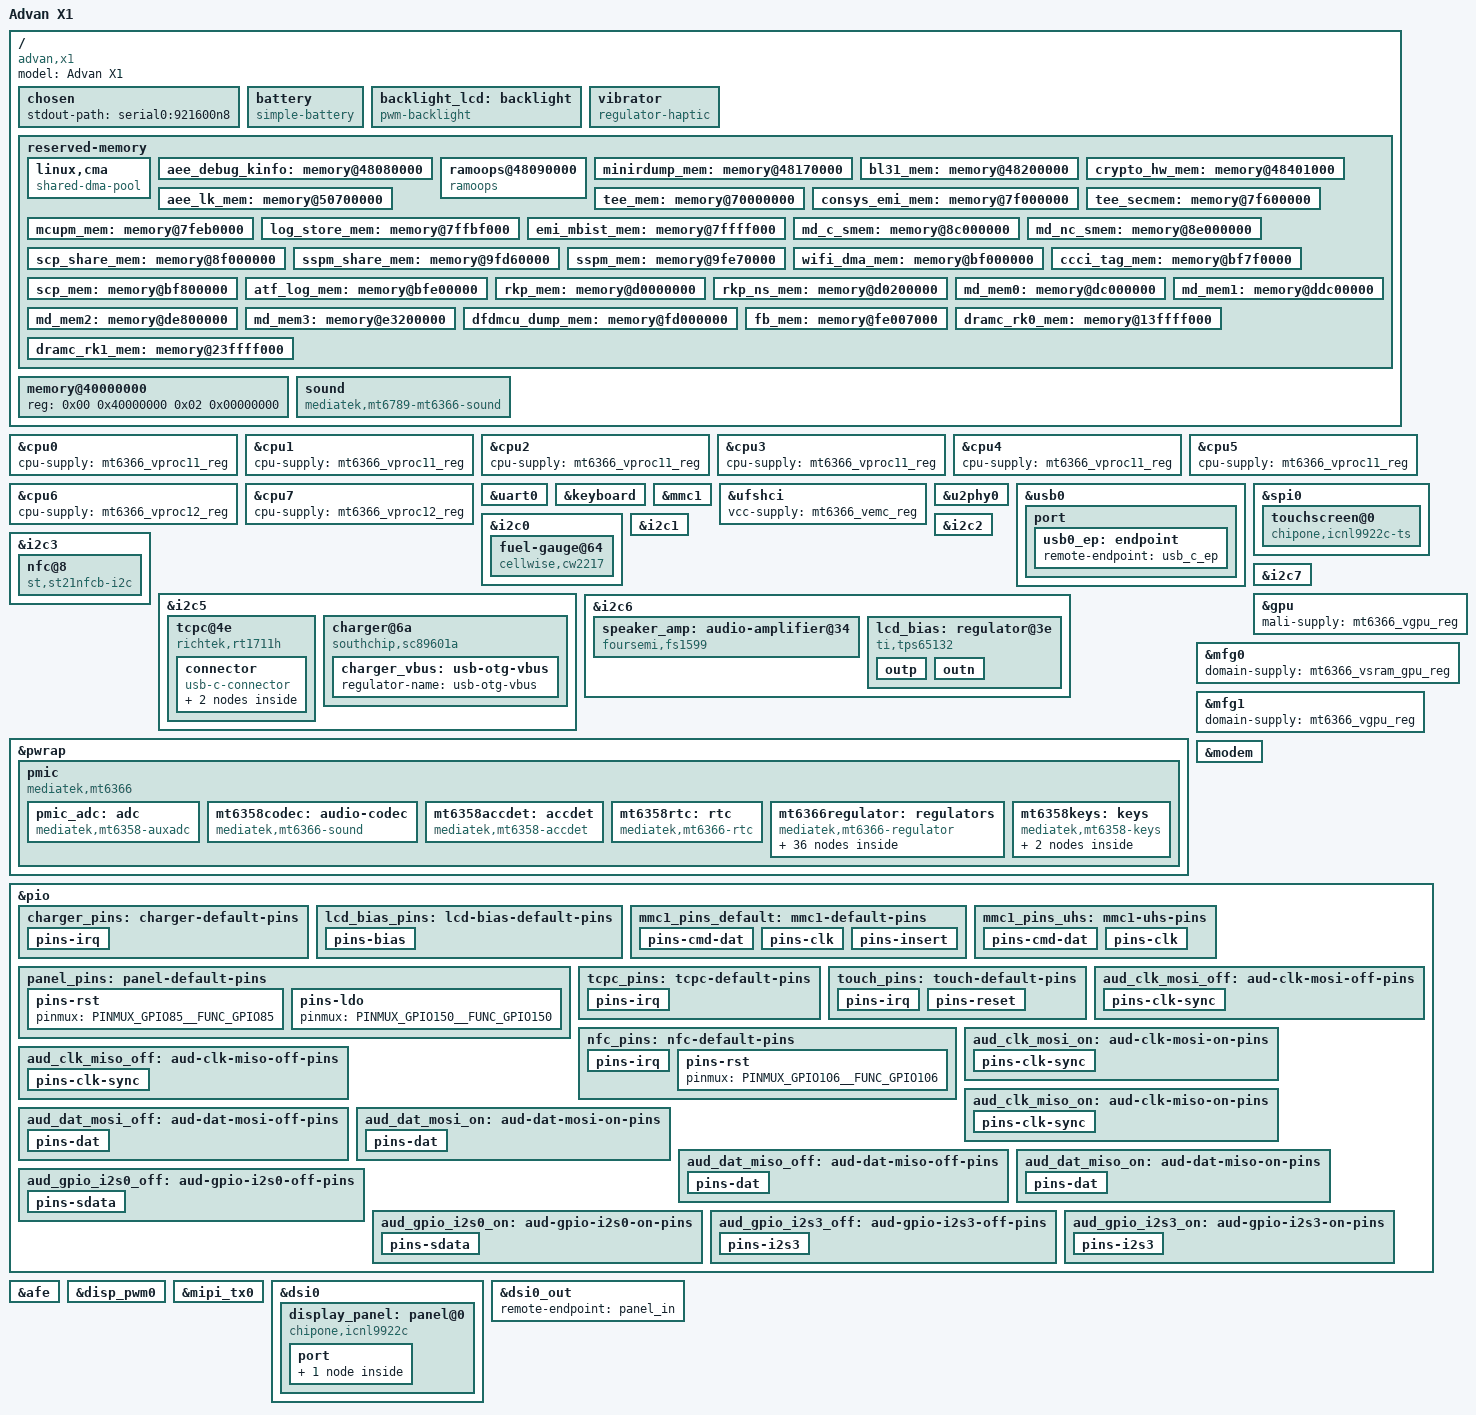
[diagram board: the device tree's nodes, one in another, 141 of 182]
// SPDX-License-Identifier: GPL-2.0-or-later
/*
 * Device Tree Source for the Advan X1 smartphone (MediaTek MT6789).
 *
 * Copyright (c) 2026 sysretq0 <sysretq0@proton.me>
 */

/dts-v1/;

#include <dt-bindings/gpio/gpio.h>
#include <dt-bindings/iio/adc/mediatek,mt6358-auxadc.h>
#include <dt-bindings/interrupt-controller/arm-gic.h>
#include <dt-bindings/interrupt-controller/irq.h>
#include <dt-bindings/input/input.h>
#include <dt-bindings/regulator/mediatek,mt6397-regulator.h>
#include <dt-bindings/usb/pd.h>

#include "mt6789.dtsi"

/ {
	model = "Advan X1";
	compatible = "advan,x1", "mediatek,mt6789";

	chosen {
		stdout-path = "serial0:921600n8";
	};

	battery: battery {
		compatible = "simple-battery";
		charge-full-design-microamp-hours = <5000000>;
		voltage-min-design-microvolt = <3400000>;
		voltage-max-design-microvolt = <4450000>;
		constant-charge-voltage-max-microvolt = <4450000>;
		constant-charge-current-max-microamp = <2000000>;
	};

	backlight_lcd: backlight {
		compatible = "pwm-backlight";
		pwms = <&disp_pwm0 0 39385>;
		brightness-levels = <0 1024 2048 4096 8192 16384 32768 65535>;
		num-interpolated-steps = <16>;
		default-brightness-level = <80>;
		status = "okay";
	};

	vibrator {
		compatible = "regulator-haptic";
		haptic-supply = <&mt6366_vibr_reg>;
		min-microvolt = <3000000>;
		max-microvolt = <3300000>;
	};

	reserved-memory {
		#address-cells = <2>;
		#size-cells = <2>;
		ranges;

		/*
		 * Constrain CMA below 4 GiB (0x100000000) for 32-bit DMA
		 * peripherals (AFE, MMC, SPI) and M4U page-table allocations.
		 * Memblock skips all no-map carveouts below (live placement
		 * verified at 0x68c00000..0x6cbfffff).
		 */
		linux,cma {
			compatible = "shared-dma-pool";
			reusable;
			size = <0x00 0x04000000>;
			alloc-ranges = <0x00 0x40000000 0x00 0xc0000000>;
			linux,cma-default;
		};

		/*
		 * Stock Advan X1 LK/EMI-MPU no-map carveouts (all 31 RES[0..30]
		 * regions from pl_lk.txt = 313.55 MiB, leaving 7878.45 MiB /
		 * ~7.69 GiB usable out of 8 GiB physical LPDDR4X).
		 */
		aee_debug_kinfo: memory@48080000 {
			reg = <0x00 0x48080000 0x00 0x00010000>;
			no-map;
		};

		/*
		 * Bootloader ramoops carveout: 896 KiB window at 0x48090000.
		 */
		ramoops@48090000 {
			compatible = "ramoops";
			reg = <0x00 0x48090000 0x00 0x000e0000>;
			record-size = <0x1000>;
			console-size = <0x40000>;
			ftrace-size = <0x1000>;
			pmsg-size = <0x10000>;
			ecc-size = <0>;
			no-map;
		};

		minirdump_mem: memory@48170000 {
			reg = <0x00 0x48170000 0x00 0x00010000>;
			no-map;
		};

		bl31_mem: memory@48200000 {
			reg = <0x00 0x48200000 0x00 0x00200000>;
			no-map;
		};

		crypto_hw_mem: memory@48401000 {
			reg = <0x00 0x48401000 0x00 0x00001000>;
			no-map;
		};

		aee_lk_mem: memory@50700000 {
			reg = <0x00 0x50700000 0x00 0x00800000>;
			no-map;
		};

		tee_mem: memory@70000000 {
			reg = <0x00 0x70000000 0x00 0x06c00000>;
			no-map;
		};

		consys_emi_mem: memory@7f000000 {
			reg = <0x00 0x7f000000 0x00 0x00500000>;
			no-map;
		};

		tee_secmem: memory@7f600000 {
			reg = <0x00 0x7f600000 0x00 0x00800000>;
			no-map;
		};

		mcupm_mem: memory@7feb0000 {
			reg = <0x00 0x7feb0000 0x00 0x00100000>;
			no-map;
		};

		log_store_mem: memory@7ffbf000 {
			reg = <0x00 0x7ffbf000 0x00 0x00040000>;
			no-map;
		};

		emi_mbist_mem: memory@7ffff000 {
			reg = <0x00 0x7ffff000 0x00 0x00001000>;
			no-map;
		};

		/*
		 * Advan X1 LK-configured EMI MPU regions for the integrated
		 * Gen95 modem (md1img DRAM at 0xdc000000, AP-MD SMEM, CCCI
		 * tags, SCP DRAM), verified from stock runtime_merged.dts
		 * (mblock-20..28) and live telemetry.
		 */
		md_c_smem: memory@8c000000 {
			reg = <0x00 0x8c000000 0x00 0x016a0000>;
			no-map;
		};

		md_nc_smem: memory@8e000000 {
			reg = <0x00 0x8e000000 0x00 0x00e10000>;
			no-map;
		};

		scp_share_mem: memory@8f000000 {
			reg = <0x00 0x8f000000 0x00 0x007a0000>;
			no-map;
		};

		sspm_share_mem: memory@9fd60000 {
			reg = <0x00 0x9fd60000 0x00 0x00110000>;
			no-map;
		};

		sspm_mem: memory@9fe70000 {
			reg = <0x00 0x9fe70000 0x00 0x00180000>;
			no-map;
		};

		wifi_dma_mem: memory@bf000000 {
			reg = <0x00 0xbf000000 0x00 0x00600000>;
			no-map;
		};

		ccci_tag_mem: memory@bf7f0000 {
			reg = <0x00 0xbf7f0000 0x00 0x00010000>;
			no-map;
		};

		scp_mem: memory@bf800000 {
			reg = <0x00 0xbf800000 0x00 0x00600000>;
			no-map;
		};

		atf_log_mem: memory@bfe00000 {
			reg = <0x00 0xbfe00000 0x00 0x00200000>;
			no-map;
		};

		rkp_mem: memory@d0000000 {
			reg = <0x00 0xd0000000 0x00 0x00200000>;
			no-map;
		};

		rkp_ns_mem: memory@d0200000 {
			reg = <0x00 0xd0200000 0x00 0x00200000>;
			no-map;
		};

		md_mem0: memory@dc000000 {
			reg = <0x00 0xdc000000 0x00 0x013f0000>;
			no-map;
		};

		md_mem1: memory@ddc00000 {
			reg = <0x00 0xddc00000 0x00 0x00430000>;
			no-map;
		};

		md_mem2: memory@de800000 {
			reg = <0x00 0xde800000 0x00 0x02c40000>;
			no-map;
		};

		md_mem3: memory@e3200000 {
			reg = <0x00 0xe3200000 0x00 0x00e00000>;
			no-map;
		};

		dfdmcu_dump_mem: memory@fd000000 {
			reg = <0x00 0xfd000000 0x00 0x00100000>;
			no-map;
		};

		fb_mem: memory@fe007000 {
			reg = <0x00 0xfe007000 0x00 0x01ff8000>;
			no-map;
		};

		dramc_rk0_mem: memory@13ffff000 {
			reg = <0x01 0x3ffff000 0x00 0x00001000>;
			no-map;
		};

		dramc_rk1_mem: memory@23ffff000 {
			reg = <0x02 0x3ffff000 0x00 0x00001000>;
			no-map;
		};
	};

	memory@40000000 {
		device_type = "memory";
		reg = <0x00 0x40000000 0x02 0x00000000>;
	};

	sound {
		compatible = "mediatek,mt6789-mt6366-sound";
		model = "mt6789-mt6366";
		mediatek,platform = <&afe>;
		mediatek,accdet = <&mt6358accdet>;
		aux-devs = <&speaker_amp>;
		pinctrl-names = "aud_clk_mosi_off",
				"aud_clk_mosi_on",
				"aud_clk_miso_off",
				"aud_clk_miso_on",
				"aud_dat_miso_off",
				"aud_dat_miso_on",
				"aud_dat_mosi_off",
				"aud_dat_mosi_on",
				"aud_gpio_i2s0_off",
				"aud_gpio_i2s0_on",
				"aud_gpio_i2s3_off",
				"aud_gpio_i2s3_on";
		pinctrl-0 = <&aud_clk_mosi_off>;
		pinctrl-1 = <&aud_clk_mosi_on>;
		pinctrl-2 = <&aud_clk_miso_off>;
		pinctrl-3 = <&aud_clk_miso_on>;
		pinctrl-4 = <&aud_dat_miso_off>;
		pinctrl-5 = <&aud_dat_miso_on>;
		pinctrl-6 = <&aud_dat_mosi_off>;
		pinctrl-7 = <&aud_dat_mosi_on>;
		pinctrl-8 = <&aud_gpio_i2s0_off>;
		pinctrl-9 = <&aud_gpio_i2s0_on>;
		pinctrl-10 = <&aud_gpio_i2s3_off>;
		pinctrl-11 = <&aud_gpio_i2s3_on>;
		audio-routing = "Ext Spk IN", "LINEOUT L",
				"Speaker", "Ext Spk OUT",
				"Headphone", "Headphone L",
				"Headphone", "Headphone R",
				"Earpiece", "Receiver",
				"AIN0", "Main Mic",
				"AIN1", "Headset Mic",
				"AIN2", "Sub Mic";
	};
};

&cpu0 {
	cpu-supply = <&mt6366_vproc11_reg>;
};

&cpu1 {
	cpu-supply = <&mt6366_vproc11_reg>;
};

&cpu2 {
	cpu-supply = <&mt6366_vproc11_reg>;
};

&cpu3 {
	cpu-supply = <&mt6366_vproc11_reg>;
};

&cpu4 {
	cpu-supply = <&mt6366_vproc11_reg>;
};

&cpu5 {
	cpu-supply = <&mt6366_vproc11_reg>;
};

&cpu6 {
	cpu-supply = <&mt6366_vproc12_reg>;
};

&cpu7 {
	cpu-supply = <&mt6366_vproc12_reg>;
};

&uart0 {
	status = "okay";
};

&keyboard {
	keypad,num-rows = <1>;
	keypad,num-columns = <1>;
	linux,keymap = <MATRIX_KEY(0x00, 0x00, KEY_VOLUMEDOWN)>;
	wakeup-source;
	status = "okay";
};

&mmc1 {
	pinctrl-names = "default", "state_uhs";
	pinctrl-0 = <&mmc1_pins_default>;
	pinctrl-1 = <&mmc1_pins_uhs>;
	bus-width = <4>;
	max-frequency = <200000000>;
	cap-sd-highspeed;
	sd-uhs-sdr12;
	sd-uhs-sdr25;
	sd-uhs-sdr50;
	sd-uhs-sdr104;
	sd-uhs-ddr50;
	no-mmc;
	no-sdio;
	cd-gpios = <&pio 7 GPIO_ACTIVE_HIGH>;
	vmmc-supply = <&mt6366_vmch_reg>;
	vqmmc-supply = <&mt6366_vmc_reg>;
	status = "okay";
};

&ufshci {
	vcc-supply = <&mt6366_vemc_reg>;
	status = "okay";
};

&u2phy0 {
	status = "okay";
};

&usb0 {
	dr_mode = "otg";
	usb-role-switch;
	status = "okay";

	port {
		usb0_ep: endpoint {
			remote-endpoint = <&usb_c_ep>;
		};
	};
};

&spi0 {
	pinctrl-names = "default";
	pinctrl-0 = <&spi0_pins>;
	mediatek,pad-select = <0>;
	status = "okay";

	touchscreen@0 {
		compatible = "chipone,icnl9922c-ts";
		reg = <0>;
		spi-max-frequency = <3000000>;
		panel = <&display_panel>;
		/*
		 * Active-low hardware reset (gpiod logical 1 = physical LOW,
		 * 0 = physical HIGH; verified out-hi ACTIVE LOW while running).
		 */
		reset-gpios = <&pio 107 GPIO_ACTIVE_LOW>;
		pinctrl-names = "default";
		pinctrl-0 = <&touch_pins>;
		interrupt-parent = <&pio>;
		interrupts = <9 IRQ_TYPE_EDGE_FALLING>;
		touchscreen-size-x = <1080>;
		touchscreen-size-y = <2460>;
		/* Matches panel-chipone-icnl9922c.c display_info (6.78" 9:20.5) */
		touchscreen-x-mm = <70>;
		touchscreen-y-mm = <160>;
	};
};

&i2c0 {
	pinctrl-names = "default";
	pinctrl-0 = <&i2c0_pins>;
	clock-frequency = <400000>;
	status = "okay";

	fuel-gauge@64 {
		compatible = "cellwise,cw2217";
		reg = <0x64>;
		shunt-resistor-micro-ohms = <5000>;
		monitored-battery = <&battery>;
		cellwise,battery-profile = /bits/ 8 <
			0x5a 0x00 0x00 0x00 0x00 0x00 0x00 0x00
			0xa8 0xb2 0xb9 0xb7 0xa4 0x9d 0xe2 0xd1
			0xc7 0xff 0xdb 0x9c 0x8a 0x71 0x61 0x56
			0x4f 0x4d 0x49 0xac 0x9a 0xde 0x53 0xc4
			0xb9 0xc5 0xce 0xd4 0xd5 0xd3 0xd1 0xcd
			0xcb 0xd1 0xd7 0xb4 0xa2 0x96 0x8d 0x86
			0x81 0x83 0x8a 0x93 0xa9 0x85 0x68 0x5f
			0x20 0x00 0xab 0x10 0x00 0xa0 0x7a 0x00
			0x00 0x00 0x64 0x20 0xc3 0x83 0x00 0x00
			0x00 0x00 0x00 0x00 0x00 0x00 0x00 0x40
		>;
	};
};

&i2c1 {
	pinctrl-names = "default";
	pinctrl-0 = <&i2c1_pins>;
	clock-frequency = <400000>;
	status = "okay";
};

&i2c2 {
	pinctrl-names = "default";
	pinctrl-0 = <&i2c2_pins>;
	clock-frequency = <400000>;
	status = "okay";
};

&i2c3 {
	pinctrl-names = "default";
	pinctrl-0 = <&i2c3_pins>;
	clock-frequency = <400000>;
	status = "okay";

	nfc@8 {
		compatible = "st,st21nfcb-i2c";
		reg = <0x08>;
		pinctrl-names = "default";
		pinctrl-0 = <&nfc_pins>;
		interrupt-parent = <&pio>;
		interrupts = <1 IRQ_TYPE_LEVEL_HIGH>;
		reset-gpios = <&pio 106 GPIO_ACTIVE_HIGH>;
	};
};

&i2c5 {
	pinctrl-names = "default";
	pinctrl-0 = <&i2c5_pins>;
	clock-frequency = <400000>;
	status = "okay";

	tcpc@4e {
		compatible = "richtek,rt1711h";
		reg = <0x4e>;
		pinctrl-names = "default";
		pinctrl-0 = <&tcpc_pins>;
		interrupt-parent = <&pio>;
		interrupts = <13 IRQ_TYPE_LEVEL_LOW>;
		vbus-supply = <&charger_vbus>;
		wakeup-source;

		connector {
			compatible = "usb-c-connector";
			label = "USB-C";
			power-role = "dual";
			data-role = "dual";
			try-power-role = "sink";
			source-pdos = <PDO_FIXED(5000, 1000, PDO_FIXED_USB_COMM)>;
			sink-pdos = <PDO_FIXED(5000, 2000, PDO_FIXED_USB_COMM)>;
			op-sink-microwatt = <10000000>;

			port {
				usb_c_ep: endpoint {
					remote-endpoint = <&usb0_ep>;
				};
			};
		};
	};

	charger@6a {
		compatible = "southchip,sc89601a", "ti,bq25890";
		reg = <0x6a>;
		pinctrl-names = "default";
		pinctrl-0 = <&charger_pins>;
		interrupt-parent = <&pio>;
		interrupts = <12 IRQ_TYPE_EDGE_FALLING>;
		ti,battery-regulation-voltage = <4450000>;
		ti,charge-current = <2000000>;
		ti,termination-current = <250000>;
		ti,precharge-current = <480000>;
		ti,minimum-sys-voltage = <3500000>;
		ti,boost-voltage = <5000000>;
		ti,boost-max-current = <1200000>;
		monitored-battery = <&battery>;

		charger_vbus: usb-otg-vbus {
			regulator-name = "usb-otg-vbus";
		};
	};
};

&i2c6 {
	pinctrl-names = "default";
	pinctrl-0 = <&i2c6_pins>;
	clock-frequency = <400000>;
	status = "okay";

	speaker_amp: audio-amplifier@34 {
		compatible = "foursemi,fs1599";
		reg = <0x34>;
		sound-name-prefix = "Ext Spk";
	};

	lcd_bias: regulator@3e {
		compatible = "ti,tps65132";
		reg = <0x3e>;
		pinctrl-names = "default";
		pinctrl-0 = <&lcd_bias_pins>;

		outp: outp {
			regulator-name = "lcd_bias_outp";
			regulator-min-microvolt = <5800000>;
			regulator-max-microvolt = <5800000>;
			regulator-boot-on;
			enable-gpios = <&pio 108 GPIO_ACTIVE_HIGH>;
		};

		outn: outn {
			regulator-name = "lcd_bias_outn";
			regulator-min-microvolt = <5800000>;
			regulator-max-microvolt = <5800000>;
			regulator-boot-on;
			enable-gpios = <&pio 109 GPIO_ACTIVE_HIGH>;
		};
	};
};

&i2c7 {
	pinctrl-names = "default";
	pinctrl-0 = <&i2c7_pins>;
	clock-frequency = <400000>;
	status = "okay";
};

&pwrap {
	status = "okay";

	pmic: pmic {
		compatible = "mediatek,mt6366", "mediatek,mt6358";
		interrupt-parent = <&pio>;
		interrupts = <137 IRQ_TYPE_LEVEL_HIGH>;
		interrupt-controller;
		#interrupt-cells = <2>;

		pmic_adc: adc {
			compatible = "mediatek,mt6358-auxadc";
			#io-channel-cells = <1>;
		};

		mt6358codec: audio-codec {
			compatible = "mediatek,mt6366-sound", "mediatek,mt6358-sound";
			Avdd-supply = <&mt6366_vaud28_reg>;
			mediatek,dmic-mode = <0>;
		};

		mt6358accdet: accdet {
			compatible = "mediatek,mt6358-accdet";
			io-channels = <&pmic_adc MT6358_AUXADC_ACCDET>;
			io-channel-names = "pmic_accdet";
			mediatek,mic-vol = <6>;
			mediatek,mic-mode = <1>;
			mediatek,plugout-debounce = <1>;
			mediatek,eint-level-pol = <8>;
			mediatek,pwm-deb-setting = <0x500 0x500 0x01 0x1f0
						    0x800 0x800 0x20 0x44
						    0x00 0x00 0x0e 0x00
						    0x00 0x00 0x00>;
			mediatek,three-key-threshold = <0 80 220 400>;
			mediatek,four-key-threshold = <0 58 121 192 400>;
		};

		mt6358rtc: rtc {
			compatible = "mediatek,mt6366-rtc", "mediatek,mt6358-rtc";
		};

		mt6366regulator: regulators {
			compatible = "mediatek,mt6366-regulator", "mediatek,mt6358-regulator";

			vcore {
				regulator-name = "vcore";
				regulator-min-microvolt = <500000>;
				regulator-max-microvolt = <1293750>;
				regulator-ramp-delay = <6250>;
				regulator-enable-ramp-delay = <200>;
				regulator-allowed-modes = <MT6397_BUCK_MODE_AUTO
							   MT6397_BUCK_MODE_FORCE_PWM>;
				regulator-always-on;
			};

			mt6366_vdram1_reg: vdram1 {
				regulator-name = "vdram1";
				regulator-min-microvolt = <500000>;
				regulator-max-microvolt = <2087500>;
				regulator-ramp-delay = <12500>;
				regulator-enable-ramp-delay = <0>;
				regulator-allowed-modes = <MT6397_BUCK_MODE_AUTO
							   MT6397_BUCK_MODE_FORCE_PWM>;
				regulator-always-on;
			};

			mt6366_vgpu_reg: vgpu {
				regulator-name = "vgpu";
				regulator-min-microvolt = <500000>;
				regulator-max-microvolt = <950000>;
				regulator-ramp-delay = <6250>;
				regulator-enable-ramp-delay = <200>;
				regulator-allowed-modes = <MT6397_BUCK_MODE_AUTO
							   MT6397_BUCK_MODE_FORCE_PWM>;
				regulator-coupled-with = <&mt6366_vsram_gpu_reg>;
				regulator-coupled-max-spread = <100000>;
				regulator-boot-on;
			};

			mt6366_vproc11_reg: vproc11 {
				regulator-name = "vproc11";
				regulator-min-microvolt = <500000>;
				regulator-max-microvolt = <1293750>;
				regulator-ramp-delay = <6250>;
				regulator-enable-ramp-delay = <200>;
				regulator-allowed-modes = <MT6397_BUCK_MODE_AUTO
							   MT6397_BUCK_MODE_FORCE_PWM>;
				regulator-always-on;
			};

			mt6366_vproc12_reg: vproc12 {
				regulator-name = "vproc12";
				regulator-min-microvolt = <500000>;
				regulator-max-microvolt = <1293750>;
				regulator-ramp-delay = <6250>;
				regulator-enable-ramp-delay = <200>;
				regulator-allowed-modes = <MT6397_BUCK_MODE_AUTO
							   MT6397_BUCK_MODE_FORCE_PWM>;
				regulator-always-on;
			};

			mt6366_vs1_reg: vs1 {
				regulator-name = "vs1";
				regulator-min-microvolt = <1000000>;
				regulator-max-microvolt = <2587500>;
				regulator-ramp-delay = <12500>;
				regulator-enable-ramp-delay = <0>;
				regulator-always-on;
			};

			mt6366_vs2_reg: vs2 {
				regulator-name = "vs2";
				regulator-min-microvolt = <500000>;
				regulator-max-microvolt = <2087500>;
				regulator-ramp-delay = <12500>;
				regulator-enable-ramp-delay = <0>;
				regulator-always-on;
			};

			mt6366_vmodem_reg: vmodem {
				regulator-name = "vmodem";
				regulator-min-microvolt = <500000>;
				regulator-max-microvolt = <1293750>;
				regulator-ramp-delay = <6250>;
				regulator-enable-ramp-delay = <900>;
				regulator-always-on;
			};

			mt6366_vpa_reg: vpa {
				regulator-name = "vpa";
				regulator-min-microvolt = <500000>;
				regulator-max-microvolt = <3650000>;
				regulator-ramp-delay = <50000>;
				regulator-enable-ramp-delay = <250>;
			};

			mt6366_va12_reg: va12 {
				regulator-name = "va12";
				regulator-min-microvolt = <1200000>;
				regulator-max-microvolt = <1200000>;
				regulator-enable-ramp-delay = <270>;
				regulator-always-on;
			};

			mt6366_vaud28_reg: vaud28 {
				regulator-name = "vaud28";
				regulator-min-microvolt = <2800000>;
				regulator-max-microvolt = <2800000>;
				regulator-enable-ramp-delay = <270>;
			};

			mt6366_vaux18_reg: vaux18 {
				regulator-name = "vaux18";
				regulator-min-microvolt = <1800000>;
				regulator-max-microvolt = <1800000>;
				regulator-enable-ramp-delay = <270>;
				regulator-always-on;
			};

			mt6366_vbif28_reg: vbif28 {
				regulator-name = "vbif28";
				regulator-min-microvolt = <2800000>;
				regulator-max-microvolt = <2800000>;
				regulator-enable-ramp-delay = <270>;
				regulator-always-on;
			};

			mt6366_vcn18_reg: vcn18 {
				regulator-name = "vcn18";
				regulator-min-microvolt = <1800000>;
				regulator-max-microvolt = <1800000>;
				regulator-enable-ramp-delay = <270>;
			};

			mt6366_vcn28_reg: vcn28 {
				regulator-name = "vcn28";
				regulator-min-microvolt = <2800000>;
				regulator-max-microvolt = <2800000>;
				regulator-enable-ramp-delay = <270>;
				regulator-always-on;
			};

			mt6366_vefuse_reg: vefuse {
				regulator-name = "vefuse";
				regulator-min-microvolt = <1700000>;
				regulator-max-microvolt = <1900000>;
				regulator-enable-ramp-delay = <270>;
			};

			mt6366_vfe28_reg: vfe28 {
				regulator-name = "vfe28";
				regulator-min-microvolt = <2800000>;
				regulator-max-microvolt = <2800000>;
				regulator-enable-ramp-delay = <270>;
			};

			mt6366_vemc_reg: vemc {
				regulator-name = "vemc";
				regulator-min-microvolt = <2900000>;
				regulator-max-microvolt = <3300000>;
				regulator-enable-ramp-delay = <60>;
			};

			mt6366_vibr_reg: vibr {
				regulator-name = "vibr";
				regulator-min-microvolt = <1200000>;
				regulator-max-microvolt = <3300000>;
				regulator-enable-ramp-delay = <60>;
			};

			mt6366_vio18_reg: vio18 {
				regulator-name = "vio18";
				regulator-min-microvolt = <1800000>;
				regulator-max-microvolt = <1800000>;
				regulator-enable-ramp-delay = <2700>;
				regulator-always-on;
			};

			mt6366_vusb_reg: vusb {
				regulator-name = "vusb";
				regulator-min-microvolt = <3000000>;
				regulator-max-microvolt = <3100000>;
				regulator-enable-ramp-delay = <270>;
				regulator-always-on;
			};

			mt6366_vio28_reg: vio28 {
				regulator-name = "vio28";
				regulator-min-microvolt = <2800000>;
				regulator-max-microvolt = <2800000>;
				regulator-enable-ramp-delay = <270>;
				regulator-always-on;
			};

			mt6366_vm18_reg: vm18 {
				regulator-name = "vm18";
				regulator-min-microvolt = <1800000>;
				regulator-max-microvolt = <1800000>;
				regulator-enable-ramp-delay = <325>;
				regulator-always-on;
			};

			mt6366_vmc_reg: vmc {
				regulator-name = "vmc";
				regulator-min-microvolt = <1800000>;
				regulator-max-microvolt = <3300000>;
				regulator-enable-ramp-delay = <60>;
			};

			mt6366_vmch_reg: vmch {
				regulator-name = "vmch";
				regulator-min-microvolt = <2900000>;
				regulator-max-microvolt = <3300000>;
				regulator-enable-ramp-delay = <60>;
			};

			mt6366_vcn33_reg: vcn33 {
				regulator-name = "vcn33";
				regulator-min-microvolt = <3300000>;
				regulator-max-microvolt = <3500000>;
				regulator-enable-ramp-delay = <270>;
			};

			mt6366_vdram2_reg: vdram2 {
				regulator-name = "vdram2";
				regulator-min-microvolt = <600000>;
				regulator-max-microvolt = <1800000>;
				regulator-enable-ramp-delay = <3300>;
				regulator-always-on;
			};

			mt6366_vrf12_reg: vrf12 {
				regulator-name = "vrf12";
				regulator-min-microvolt = <1200000>;
				regulator-max-microvolt = <1200000>;
				regulator-enable-ramp-delay = <120>;
			};

			mt6366_vrf18_reg: vrf18 {
				regulator-name = "vrf18";
				regulator-min-microvolt = <1800000>;
				regulator-max-microvolt = <1800000>;
				regulator-enable-ramp-delay = <120>;
			};

			mt6366_vsim1_reg: vsim1 {
				regulator-name = "vsim1";
				regulator-min-microvolt = <1700000>;
				regulator-max-microvolt = <3100000>;
				regulator-enable-ramp-delay = <540>;
			};

			mt6366_vsim2_reg: vsim2 {
				regulator-name = "vsim2";
				regulator-min-microvolt = <1700000>;
				regulator-max-microvolt = <3100000>;
				regulator-enable-ramp-delay = <540>;
			};

			mt6366_vsram_gpu_reg: vsram-gpu {
				regulator-name = "vsram_gpu";
				regulator-min-microvolt = <750000>;
				regulator-max-microvolt = <1050000>;
				regulator-ramp-delay = <6250>;
				regulator-enable-ramp-delay = <240>;
				regulator-coupled-with = <&mt6366_vgpu_reg>;
				regulator-coupled-max-spread = <100000>;
				regulator-boot-on;
			};

			mt6366_vsram_others_reg: vsram-others {
				regulator-name = "vsram-others";
				regulator-min-microvolt = <500000>;
				regulator-max-microvolt = <1293750>;
				regulator-ramp-delay = <6250>;
				regulator-enable-ramp-delay = <240>;
				regulator-always-on;
			};

			mt6366_vsram_proc11_reg: vsram-proc11 {
				regulator-name = "vsram-proc11";
				regulator-min-microvolt = <500000>;
				regulator-max-microvolt = <1293750>;
				regulator-ramp-delay = <6250>;
				regulator-enable-ramp-delay = <240>;
				regulator-always-on;
			};

			mt6366_vsram_proc12_reg: vsram-proc12 {
				regulator-name = "vsram-proc12";
				regulator-min-microvolt = <500000>;
				regulator-max-microvolt = <1293750>;
				regulator-ramp-delay = <6250>;
				regulator-enable-ramp-delay = <240>;
				regulator-always-on;
			};

			mt6366_vsram_core_reg: vsram-core {
				regulator-name = "vsram-core";
				regulator-min-microvolt = <500000>;
				regulator-max-microvolt = <1293750>;
				regulator-ramp-delay = <6250>;
				regulator-enable-ramp-delay = <240>;
				regulator-always-on;
			};
		};

		mt6358keys: keys {
			compatible = "mediatek,mt6358-keys";
			mediatek,long-press-mode = <1>;
			power-off-time-sec = <0>;

			power {
				linux,keycodes = <KEY_POWER>;
				wakeup-source;
			};

			home {
				linux,keycodes = <KEY_VOLUMEUP>;
				wakeup-source;
			};
		};
	};
};

&gpu {
	mali-supply = <&mt6366_vgpu_reg>;
	status = "okay";
};

&mfg0 {
	domain-supply = <&mt6366_vsram_gpu_reg>;
};

&mfg1 {
	domain-supply = <&mt6366_vgpu_reg>;
};

&modem {
	memory-region = <&md_nc_smem>, <&md_c_smem>, <&ccci_tag_mem>,
			<&md_mem0>, <&md_mem1>, <&md_mem2>, <&md_mem3>;
	memory-region-names = "nc-smem", "c-smem", "ccci-tag",
			      "md-mem0", "md-mem1", "md-mem2", "md-mem3";
	vmodem-supply = <&mt6366_vmodem_reg>;
	vsram-supply = <&mt6366_vsram_core_reg>;
	status = "okay";
};

&pio {
	charger_pins: charger-default-pins {
		pins-irq {
			pinmux = <PINMUX_GPIO12__FUNC_GPIO12>;
			input-enable;
			bias-pull-up;
		};
	};

	lcd_bias_pins: lcd-bias-default-pins {
		pins-bias {
			pinmux = <PINMUX_GPIO108__FUNC_GPIO108>,
				 <PINMUX_GPIO109__FUNC_GPIO109>;
			output-high;
		};
	};

	mmc1_pins_default: mmc1-default-pins {
		pins-cmd-dat {
			pinmux = <PINMUX_GPIO72__FUNC_MSDC1_CMD>,
				 <PINMUX_GPIO73__FUNC_MSDC1_DAT0>,
				 <PINMUX_GPIO74__FUNC_MSDC1_DAT1>,
				 <PINMUX_GPIO75__FUNC_MSDC1_DAT2>,
				 <PINMUX_GPIO76__FUNC_MSDC1_DAT3>;
			input-enable;
			drive-strength = <4>;
			bias-pull-up = <MTK_PUPD_SET_R1R0_01>;
		};

		pins-clk {
			pinmux = <PINMUX_GPIO71__FUNC_MSDC1_CLK>;
			drive-strength = <4>;
			bias-pull-down = <MTK_PUPD_SET_R1R0_10>;
		};

		pins-insert {
			pinmux = <PINMUX_GPIO7__FUNC_GPIO7>;
			input-enable;
			bias-pull-up;
		};
	};

	mmc1_pins_uhs: mmc1-uhs-pins {
		pins-cmd-dat {
			pinmux = <PINMUX_GPIO72__FUNC_MSDC1_CMD>,
				 <PINMUX_GPIO73__FUNC_MSDC1_DAT0>,
				 <PINMUX_GPIO74__FUNC_MSDC1_DAT1>,
				 <PINMUX_GPIO75__FUNC_MSDC1_DAT2>,
				 <PINMUX_GPIO76__FUNC_MSDC1_DAT3>;
			input-enable;
			drive-strength = <4>;
			bias-pull-up = <MTK_PUPD_SET_R1R0_01>;
		};

		pins-clk {
			pinmux = <PINMUX_GPIO71__FUNC_MSDC1_CLK>;
			drive-strength = <4>;
			bias-pull-down = <MTK_PUPD_SET_R1R0_10>;
		};
	};

	panel_pins: panel-default-pins {
		pins-rst {
			pinmux = <PINMUX_GPIO85__FUNC_GPIO85>;
		};
		pins-ldo {
			pinmux = <PINMUX_GPIO150__FUNC_GPIO150>;
		};
	};

	tcpc_pins: tcpc-default-pins {
		pins-irq {
			pinmux = <PINMUX_GPIO13__FUNC_GPIO13>;
			input-enable;
			bias-pull-up;
		};
	};

	touch_pins: touch-default-pins {
		pins-irq {
			pinmux = <PINMUX_GPIO9__FUNC_GPIO9>;
			input-enable;
			bias-pull-up;
		};
		pins-reset {
			pinmux = <PINMUX_GPIO107__FUNC_GPIO107>;
			output-high;
		};
	};

	nfc_pins: nfc-default-pins {
		pins-irq {
			pinmux = <PINMUX_GPIO1__FUNC_GPIO1>;
			input-enable;
			bias-pull-down;
		};

		pins-rst {
			pinmux = <PINMUX_GPIO106__FUNC_GPIO106>;
		};
	};

	aud_clk_mosi_off: aud-clk-mosi-off-pins {
		pins-clk-sync {
			pinmux = <PINMUX_GPIO169__FUNC_GPIO169>,
				 <PINMUX_GPIO170__FUNC_GPIO170>;
			input-enable;
			bias-pull-down;
		};
	};

	aud_clk_mosi_on: aud-clk-mosi-on-pins {
		pins-clk-sync {
			pinmux = <PINMUX_GPIO169__FUNC_AUD_CLK_MOSI>,
				 <PINMUX_GPIO170__FUNC_AUD_SYNC_MOSI>;
		};
	};

	aud_clk_miso_off: aud-clk-miso-off-pins {
		pins-clk-sync {
			pinmux = <PINMUX_GPIO173__FUNC_GPIO173>,
				 <PINMUX_GPIO174__FUNC_GPIO174>;
			input-enable;
			bias-pull-down;
		};
	};

	aud_clk_miso_on: aud-clk-miso-on-pins {
		pins-clk-sync {
			pinmux = <PINMUX_GPIO173__FUNC_AUD_CLK_MISO>,
				 <PINMUX_GPIO174__FUNC_AUD_SYNC_MISO>;
		};
	};

	aud_dat_mosi_off: aud-dat-mosi-off-pins {
		pins-dat {
			pinmux = <PINMUX_GPIO171__FUNC_GPIO171>,
				 <PINMUX_GPIO172__FUNC_GPIO172>;
			input-enable;
			bias-pull-down;
		};
	};

	aud_dat_mosi_on: aud-dat-mosi-on-pins {
		pins-dat {
			pinmux = <PINMUX_GPIO171__FUNC_AUD_DAT_MOSI0>,
				 <PINMUX_GPIO172__FUNC_AUD_DAT_MOSI1>;
		};
	};

	aud_dat_miso_off: aud-dat-miso-off-pins {
		pins-dat {
			pinmux = <PINMUX_GPIO175__FUNC_GPIO175>,
				 <PINMUX_GPIO176__FUNC_GPIO176>;
			input-enable;
			bias-pull-down;
		};
	};

	aud_dat_miso_on: aud-dat-miso-on-pins {
		pins-dat {
			pinmux = <PINMUX_GPIO175__FUNC_AUD_DAT_MISO0>,
				 <PINMUX_GPIO176__FUNC_AUD_DAT_MISO1>;
			input-schmitt-enable;
			bias-disable;
		};
	};

	aud_gpio_i2s0_off: aud-gpio-i2s0-off-pins {
		pins-sdata {
			pinmux = <PINMUX_GPIO53__FUNC_GPIO53>;
			input-enable;
			bias-pull-down;
		};
	};

	aud_gpio_i2s0_on: aud-gpio-i2s0-on-pins {
		pins-sdata {
			pinmux = <PINMUX_GPIO53__FUNC_I2S0_DI>;
			bias-disable;
		};
	};

	aud_gpio_i2s3_off: aud-gpio-i2s3-off-pins {
		pins-i2s3 {
			pinmux = <PINMUX_GPIO50__FUNC_GPIO50>,
				 <PINMUX_GPIO51__FUNC_GPIO51>,
				 <PINMUX_GPIO52__FUNC_GPIO52>;
			input-enable;
			bias-pull-down;
		};
	};

	aud_gpio_i2s3_on: aud-gpio-i2s3-on-pins {
		pins-i2s3 {
			pinmux = <PINMUX_GPIO50__FUNC_I2S3_DO>,
				 <PINMUX_GPIO51__FUNC_I2S3_BCK>,
				 <PINMUX_GPIO52__FUNC_I2S3_LRCK>;
			bias-disable;
		};
	};
};

&afe {
	status = "okay";
};

&disp_pwm0 {
	status = "okay";
};

&mipi_tx0 {
	status = "okay";
};

&dsi0 {
	status = "okay";
	#address-cells = <1>;
	#size-cells = <0>;

	display_panel: panel@0 {
		compatible = "chipone,icnl9922c";
		reg = <0>;
		pinctrl-names = "default";
		pinctrl-0 = <&panel_pins>;

		/*
		 * Active-low panel reset (gpiod logical 1 = physical LOW,
		 * 0 = physical HIGH; matches stock raw-GPIO 0->1 waveform and
		 * verified out-hi ACTIVE LOW while display is active).
		 */
		reset-gpios = <&pio 85 GPIO_ACTIVE_LOW>;
		ldo18-gpios = <&pio 150 GPIO_ACTIVE_HIGH>;
		vsp-supply = <&outp>;
		vsn-supply = <&outn>;
		backlight = <&backlight_lcd>;

		port {
			panel_in: endpoint {
				remote-endpoint = <&dsi0_out>;
			};
		};
	};
};

&dsi0_out {
	remote-endpoint = <&panel_in>;
};
